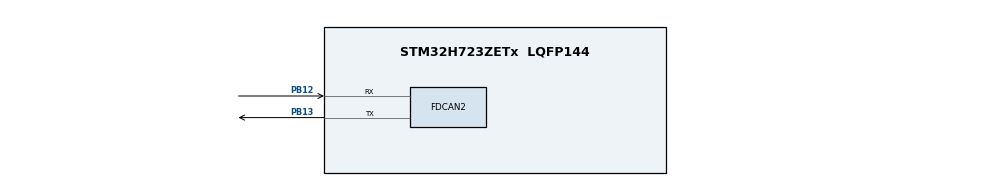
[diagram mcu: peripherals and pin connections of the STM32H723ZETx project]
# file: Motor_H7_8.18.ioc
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CORTEX_M7.CPU_DCache=Enabled
CORTEX_M7.CPU_ICache=Enabled
CORTEX_M7.Enable_S-Cortex_Memory_Protection_Unit_Region1_Settings_S=MPU_REGION_ENABLE
CORTEX_M7.IsCacheable_Spec=MPU_ACCESS_CACHEABLE
CORTEX_M7.IsShareable_Spec=MPU_ACCESS_NOT_SHAREABLE
CORTEX_M7.default_mode_Activation=1
FDCAN2.CalculateBaudRateNominal=1000000
FDCAN2.CalculateTimeBitNominal=1000
FDCAN2.CalculateTimeQuantumNominal=25.0
FDCAN2.DataTimeSeg1=29
FDCAN2.DataTimeSeg2=10
FDCAN2.ExtFiltersNbr=16
FDCAN2.NominalPrescaler=1
FDCAN2.NominalSyncJumpWidth=5
FDCAN2.NominalTimeSeg1=29
FDCAN2.NominalTimeSeg2=10
FDCAN2.RxFifo0ElmtsNbr=12
FDCAN2.RxFifo1ElmtsNbr=12
FDCAN2.StdFiltersNbr=16
FDCAN2.TxBuffersNbr=16
FDCAN2.TxFifoQueueElmtsNbr=16
Mcu.Family=STM32H7
Mcu.Name=STM32H723ZETx
Mcu.Package=LQFP144
NVIC.FDCAN2_IT0_IRQn=true\:5\:0\:true\:false\:true\:true\:true\:true
NVIC.FDCAN2_IT1_IRQn=true\:5\:0\:true\:false\:true\:true\:true\:true
NVIC.PriorityGroup=NVIC_PRIORITYGROUP_4
NVIC.TIM1_UP_IRQn=true\:15\:0\:false\:false\:true\:false\:true\:true
NVIC.TIM2_IRQn=true\:5\:0\:true\:false\:true\:true\:true\:true
NVIC.TimeBase=TIM1_UP_IRQn
NVIC.TimeBaseIP=TIM1
PB12.Mode=FDCAN_Activate
PB12.Signal=FDCAN2_RX
PB13.Mode=FDCAN_Activate
PB13.Signal=FDCAN2_TX
PH0-OSC_IN.Mode=HSE-External-Oscillator
PH0-OSC_IN.Signal=RCC_OSC_IN
PH1-OSC_OUT.Mode=HSE-External-Oscillator
PH1-OSC_OUT.Signal=RCC_OSC_OUT
ProjectManager.HeapSize=0x200
ProjectManager.StackSize=0x400
ProjectManager.TargetToolchain=MDK-ARM V5.32
RCC.ADCFreq_Value=100000000
RCC.APB1Freq_Value=137500000
RCC.APB2Freq_Value=137500000
RCC.APB3Freq_Value=137500000
RCC.APB4Freq_Value=137500000
RCC.CortexFreq_Value=550000000
RCC.D1PPRE=RCC_APB3_DIV2
RCC.D2PPRE1=RCC_APB1_DIV2
RCC.D2PPRE2=RCC_APB2_DIV2
RCC.D3PPRE=RCC_APB4_DIV2
RCC.DIVM1=2
RCC.DIVM2=2
RCC.DIVN1=44
RCC.DIVN2=16
RCC.DIVP1=1
RCC.DIVQ1=4
RCC.DIVQ2=5
RCC.FDCANCLockSelection=RCC_FDCANCLKSOURCE_PLL2
RCC.HCLKFreq_Value=275000000
RCC.HPRE=RCC_HCLK_DIV2
RCC.PLL2FRACN=0
RCC.PLL3FRACN=0
RCC.PLLFRACN=0
RCC.PLLSourceVirtual=RCC_PLLSOURCE_HSE
RCC.SYSCLKFreq_VALUE=550000000
RCC.SYSCLKSource=RCC_SYSCLKSOURCE_PLLCLK
RCC.USBFreq_Value=137500000
TIM2.Period=1000-1
TIM2.Prescaler=100-1
VP_MEMORYMAP_VS_MEMORYMAP.Mode=CurAppReg
VP_SYS_VS_tim1.Mode=TIM1
VP_TIM2_VS_ClockSourceINT.Mode=Internal
board=custom

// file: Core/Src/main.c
/* USER CODE BEGIN Header */
/**
 ******************************************************************************
 * @file           : main.c
 * @brief          : Main program body
 ******************************************************************************
 * @attention
 *
 * Copyright (c) 2026 STMicroelectronics.
 * All rights reserved.
 *
 * This software is licensed under terms that can be found in the LICENSE file
 * in the root directory of this software component.
 * If no LICENSE file comes with this software, it is provided AS-IS.
 *
 ******************************************************************************
 */
/* USER CODE END Header */
#include "main.h"
#include "fdcan.h"
#include "tim.h"
#include "gpio.h"

/* USER CODE BEGIN Includes */
#include "motor.h"
#include "pid.h"
/* USER CODE END Includes */

void SystemClock_Config(void);
static void MPU_Config(void);

/* USER CODE BEGIN 0 */
DJMotor DJ_Motor[USE_DJNUM];
/* USER CODE END 0 */

int main(void)
{

  /* MPU Configuration--------------------------------------------------------*/
  MPU_Config();

  /* Enable the CPU Cache */

  /* Enable I-Cache---------------------------------------------------------*/
  SCB_EnableICache();

  /* Enable D-Cache---------------------------------------------------------*/
  SCB_EnableDCache();

  /* MCU Configuration--------------------------------------------------------*/

  /* Reset of all peripherals, Initializes the Flash interface and the Systick. */
  HAL_Init();

  /* Configure the system clock */
  SystemClock_Config();

  /* Initialize all configured peripherals */
  MX_GPIO_Init();
  MX_FDCAN2_Init();
  MX_TIM2_Init();
  /* USER CODE BEGIN 2 */
  /* 1. 开启 FDCAN2 接收中断（开启 FIFO0 的新消息通知）*/
  HAL_FDCAN_ActivateNotification(&hfdcan2, FDCAN_IT_RX_FIFO0_NEW_MESSAGE, 0);

  /* 2. 开启 FDCAN2 错误中断，发生通讯故障立刻刹车*/
  HAL_FDCAN_ActivateNotification(&hfdcan2, FDCAN_IT_BUS_OFF | FDCAN_IT_ERROR_WARNING | FDCAN_IT_ERROR_PASSIVE, 0);

  /* 3. 启动 FDCAN2（必须调用，否则节点不 Active on bus，收发都无效）*/
  if (HAL_FDCAN_Start(&hfdcan2) != HAL_OK)
  {
    Error_Handler();
  }

  /* 4. 启动 TIM2 定时器中断（不写这句，定时器根本不计数）*/
  HAL_TIM_Base_Start_IT(&htim2);

  /* 5. 电机档案初始化 */
  DJ_Motor[0].ID = 1;
  DJ_Motor[0].param.PulsePerRound = 8192;     // 编码器一圈脉冲数
  DJ_Motor[0].param.Gear_ratio = 1.0f;        // 假设外面没有其他齿轮组
  DJ_Motor[0].param.Reduction_ratio = 36.0f;  // M3508 自身的减速比是 3591/100≈36.0
  DJ_Motor[0].param.CurrentLimit_raw = 3000;  // 电流上限 3000 原始码值 ≈ 3.6A（调试期保守，测试稳定后可上调）

  /* 6. PID 初始参数（调试期先给保守值，再边调边改）*/
  PID_Reset(&DJ_Motor[0].velPID);
  PID_Reset(&DJ_Motor[0].posPID);
  DJ_Motor[0].velPID.mode = PIDINC;  // 速度环用增量式
  DJ_Motor[0].posPID.mode = PIDPOS;
  DJ_Motor[0].velPID.KP = 0.05f;
  DJ_Motor[0].velPID.KI = 0.2f;
  DJ_Motor[0].velPID.KD = 0.0f;
  DJ_Motor[0].posPID.KP = 0.0f;      // 位置环暂不启用，参数留待需要时再调
  DJ_Motor[0].posPID.KI = 0.0f;
  DJ_Motor[0].posPID.KD = 0.0f;

  /* 7. 起步设定：低速速度模式，收到反馈稳定后再慢慢加目标 */
  DJ_Motor[0].valSet.speed_rpm = 0; // 起步目标速度 100 RPM（低）
  DJ_Motor[0].valSet.current_raw = 0;
  DJ_Motor[0].MODE_Cur = DJ_RPM;      // 进入速度模式
  DJ_Motor[0].lastRxTick = HAL_GetTick();

  /* USER CODE END 2 */

  /* Infinite loop */
  /* USER CODE BEGIN WHILE */
  while (1)
  {
    /* 主循环保持空转。控制由 TIM2 中断里的 DJMotor_Func 驱动，
    HAL_Delay(10);
    /* USER CODE END WHILE */

  }
}

  /**
   * @brief System Clock Configuration
   * @retval None
   */
  void SystemClock_Config(void)
  {
    RCC_OscInitTypeDef RCC_OscInitStruct = {0};
    RCC_ClkInitTypeDef RCC_ClkInitStruct = {0};

    /** Supply configuration update enable
     */
    HAL_PWREx_ConfigSupply(PWR_LDO_SUPPLY);

    /** Configure the main internal regulator output voltage
     */
    __HAL_PWR_VOLTAGESCALING_CONFIG(PWR_REGULATOR_VOLTAGE_SCALE0);

    while (!__HAL_PWR_GET_FLAG(PWR_FLAG_VOSRDY))
    {
    }

    /** Initializes the RCC Oscillators according to the specified parameters
     * in the RCC_OscInitTypeDef structure.
     */
    RCC_OscInitStruct.OscillatorType = RCC_OSCILLATORTYPE_HSE;
    RCC_OscInitStruct.HSEState = RCC_HSE_ON;
    RCC_OscInitStruct.PLL.PLLState = RCC_PLL_ON;
    RCC_OscInitStruct.PLL.PLLSource = RCC_PLLSOURCE_HSE;
    RCC_OscInitStruct.PLL.PLLM = 2;
    RCC_OscInitStruct.PLL.PLLN = 44;
    RCC_OscInitStruct.PLL.PLLP = 1;
    RCC_OscInitStruct.PLL.PLLQ = 4;
    RCC_OscInitStruct.PLL.PLLR = 2;
    RCC_OscInitStruct.PLL.PLLRGE = RCC_PLL1VCIRANGE_3;
    RCC_OscInitStruct.PLL.PLLVCOSEL = RCC_PLL1VCOWIDE;
    RCC_OscInitStruct.PLL.PLLFRACN = 0;
    if (HAL_RCC_OscConfig(&RCC_OscInitStruct) != HAL_OK)
    {
      Error_Handler();
    }

    /** Initializes the CPU, AHB and APB buses clocks
     */
    RCC_ClkInitStruct.ClockType = RCC_CLOCKTYPE_HCLK | RCC_CLOCKTYPE_SYSCLK | RCC_CLOCKTYPE_PCLK1 | RCC_CLOCKTYPE_PCLK2 | RCC_CLOCKTYPE_D3PCLK1 | RCC_CLOCKTYPE_D1PCLK1;
    RCC_ClkInitStruct.SYSCLKSource = RCC_SYSCLKSOURCE_PLLCLK;
    RCC_ClkInitStruct.SYSCLKDivider = RCC_SYSCLK_DIV1;
    RCC_ClkInitStruct.AHBCLKDivider = RCC_HCLK_DIV2;
    RCC_ClkInitStruct.APB3CLKDivider = RCC_APB3_DIV2;
    RCC_ClkInitStruct.APB1CLKDivider = RCC_APB1_DIV2;
    RCC_ClkInitStruct.APB2CLKDivider = RCC_APB2_DIV2;
    RCC_ClkInitStruct.APB4CLKDivider = RCC_APB4_DIV2;

    if (HAL_RCC_ClockConfig(&RCC_ClkInitStruct, FLASH_LATENCY_3) != HAL_OK)
    {
      Error_Handler();
    }
  }

  /* USER CODE BEGIN 4 */
  void HAL_FDCAN_RxFifo0Callback(FDCAN_HandleTypeDef * hfdcan, uint32_t RxFifo0ITs)
  {
    if (hfdcan->Instance == FDCAN2)
    {
      FDCAN_RxHeaderTypeDef RxHeader;
      uint8_t RxData[8];
      if (HAL_FDCAN_GetRxMessage(hfdcan, FDCAN_RX_FIFO0, &RxHeader, RxData) == HAL_OK)
      {
        DJMotor_Receive(RxHeader, RxData);
      }
    }
  }

  void HAL_TIM_PeriodElapsedCallback(TIM_HandleTypeDef * htim)
  {
    /* USER CODE BEGIN Callback 0 */

    /* USER CODE END Callback 0 */
    if (htim->Instance == TIM1)
    {
      HAL_IncTick();
    }
    /* USER CODE BEGIN Callback 1 */
    if (htim->Instance == TIM2)
    {
      DJMotor_Func(); // 每 1ms 调用一次
    }
    /* USER CODE END Callback 1 */
  }
  /* USER CODE END 4 */

  /* MPU Configuration */

  void MPU_Config(void)
  {
    MPU_Region_InitTypeDef MPU_InitStruct = {0};

    /* Disables the MPU */
    HAL_MPU_Disable();

    /** Initializes and configures the Region and the memory to be protected
     */
    MPU_InitStruct.Enable = MPU_REGION_ENABLE;
    MPU_InitStruct.Number = MPU_REGION_NUMBER0;
    MPU_InitStruct.BaseAddress = 0x0;
    MPU_InitStruct.Size = MPU_REGION_SIZE_4GB;
    MPU_InitStruct.SubRegionDisable = 0x87;
    MPU_InitStruct.TypeExtField = MPU_TEX_LEVEL0;
    MPU_InitStruct.AccessPermission = MPU_REGION_NO_ACCESS;
    MPU_InitStruct.DisableExec = MPU_INSTRUCTION_ACCESS_DISABLE;
    MPU_InitStruct.IsShareable = MPU_ACCESS_NOT_SHAREABLE;
    MPU_InitStruct.IsCacheable = MPU_ACCESS_CACHEABLE;
    MPU_InitStruct.IsBufferable = MPU_ACCESS_NOT_BUFFERABLE;

    HAL_MPU_ConfigRegion(&MPU_InitStruct);

    /** Initializes and configures the Region and the memory to be protected
     */
    MPU_InitStruct.Number = MPU_REGION_NUMBER1;
    MPU_InitStruct.Size = MPU_REGION_SIZE_32B;
    MPU_InitStruct.SubRegionDisable = 0x0;
    MPU_InitStruct.DisableExec = MPU_INSTRUCTION_ACCESS_ENABLE;
    MPU_InitStruct.IsCacheable = MPU_ACCESS_NOT_CACHEABLE;

    HAL_MPU_ConfigRegion(&MPU_InitStruct);
    /* Enables the MPU */
    HAL_MPU_Enable(MPU_PRIVILEGED_DEFAULT);
  }

  /**
   * @brief  Period elapsed callback in non blocking mode
   * @note   This function is called  when TIM1 interrupt took place, inside
   * HAL_TIM_IRQHandler(). It makes a direct call to HAL_IncTick() to increment
   * a global variable "uwTick" used as application time base.
   * @param  htim : TIM handle
   * @retval None
   */

    /* USER CODE END Callback 1 */

  /**
   * @brief  This function is executed in case of error occurrence.
   * @retval None
   */
  void Error_Handler(void)
  {
    __disable_irq();
    while (1)
    {
    }
  }
